# STM32N645 register map
File version: 1.0
CPU: CM55 r0p1, little endian, no MPU, FPU, vendor SysTick, 8 interrupt priority bits
Registers are 32-bit, read-write, reset 0x0 unless marked. A register's access mark holds for its fields unless they carry their own. Offsets are from the block's base; [hi:lo] are bit positions; {n}, {i} and the like mark numbered series; 'fields as' and 'values as' point back to an identical list.

## JPEG — JPEG codec
Base 0x48023000
Same registers: JPEG_S 0x58023000
0x00 CONFR0 wo — JPEG codec control register
  [0] START
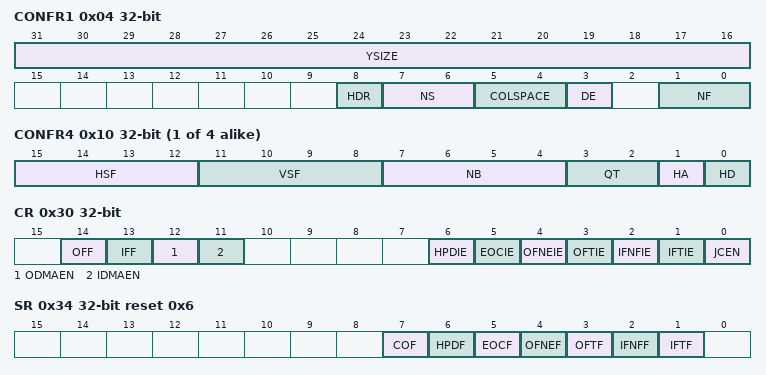
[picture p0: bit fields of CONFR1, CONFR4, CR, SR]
0x04 CONFR1 — JPEG codec configuration register 1
  [31:16] YSIZE
  [8] HDR — Header processing
  [7:6] NS — Number of components for scan
  [5:4] COLSPACE — Color space
  [3] DE — Codec operation as coder or decoder
  [1:0] NF — Number of color components
0x08 CONFR2 — JPEG codec configuration register 2
  [25:0] NMCU — Number of MCUs
0x0C CONFR3 — JPEG codec configuration register 3
  [31:16] XSIZE
{0x0+4i} CONFR{i} (i=4..7) — JPEG codec configuration register {i}
  [15:12] HSF — Horizontal sampling factor
  [11:8] VSF — Vertical sampling factor
  [7:4] NB — Number of blocks
  [3:2] QT — Quantization table
  [1] HA — Huffman AC
  [0] HD — Huffman DC
0x30 CR access per field — JPEG control register
  [14] OFF wo — Output FIFO flush
  [13] IFF wo — Input FIFO flush
  [12] ODMAEN rw — Output DMA enable
  [11] IDMAEN rw — Input DMA enable
  [6] HPDIE rw — Header parsing done interrupt enable
  [5] EOCIE rw — End of conversion interrupt enable
  [4] OFNEIE rw — Output FIFO not empty interrupt enable
  [3] OFTIE rw — Output FIFO threshold interrupt enable
  [2] IFNFIE rw — Input FIFO not full interrupt enable
  [1] IFTIE rw — Input FIFO threshold interrupt enable
  [0] JCEN rw — JPEG core enable
0x34 SR ro reset 0x6 — JPEG status register
  [7] COF — Codec operation flag
  [6] HPDF — Header parsing done flag
  [5] EOCF — End of conversion flag
  [4] OFNEF — Output FIFO not empty flag
  [3] OFTF — Output FIFO threshold flag
  [2] IFNFF — Input FIFO not full flag
  [1] IFTF — Input FIFO threshold flag
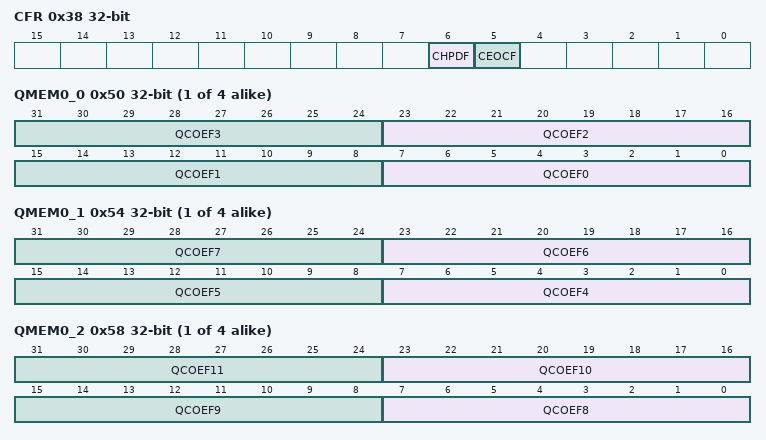
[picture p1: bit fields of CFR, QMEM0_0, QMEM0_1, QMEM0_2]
0x38 CFR — JPEG clear flag register
  [6] CHPDF — Clear header parsing done flag
  [5] CEOCF — Clear end of conversion flag
0x40 DIR wo — JPEG data input register
  [31:0] DATAIN — Data input FIFO
0x44 DOR ro — JPEG data output register
  [31:0] DATAOUT — Data output FIFO
{0x50+0x40*i} QMEM{i}_0 reset not defined (i=0..3) — JPEG quantization memory {i}
  [8n+7:8n] QCOEF{n} (n=0..3) — Quantization coefficient {n}
{0x54+0x40*i} QMEM{i}_1 reset not defined (i=0..3) — JPEG quantization memory {i}
  [8n-25:8n-32] QCOEF{n} (n=4..7) — Quantization coefficient {n}
{0x58+0x40*i} QMEM{i}_2 reset not defined (i=0..3) — JPEG quantization memory {i}
  [8n-57:8n-64] QCOEF{n} (n=8..11) — Quantization coefficient {n}
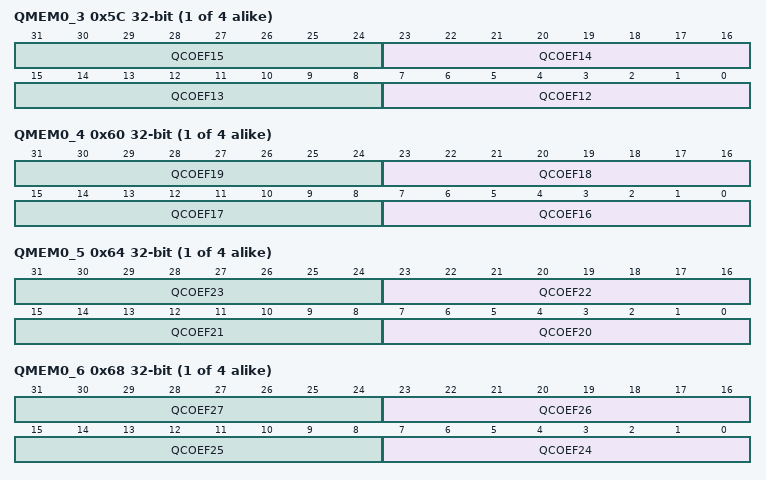
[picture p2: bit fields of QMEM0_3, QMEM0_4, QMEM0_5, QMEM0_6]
{0x5C+0x40*i} QMEM{i}_3 reset not defined (i=0..3) — JPEG quantization memory {i}
  [8n-89:8n-96] QCOEF{n} (n=12..15) — Quantization coefficient {n}
{0x60+0x40*i} QMEM{i}_4 reset not defined (i=0..3) — JPEG quantization memory {i}
  [8n-121:8n-128] QCOEF{n} (n=16..19) — Quantization coefficient {n}
{0x64+0x40*i} QMEM{i}_5 reset not defined (i=0..3) — JPEG quantization memory {i}
  [8n-153:8n-160] QCOEF{n} (n=20..23) — Quantization coefficient {n}
{0x68+0x40*i} QMEM{i}_6 reset not defined (i=0..3) — JPEG quantization memory {i}
  [8n-185:8n-192] QCOEF{n} (n=24..27) — Quantization coefficient {n}
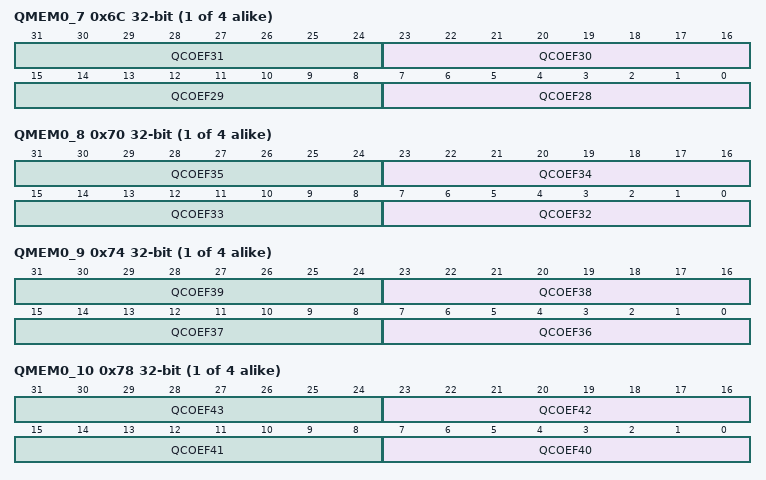
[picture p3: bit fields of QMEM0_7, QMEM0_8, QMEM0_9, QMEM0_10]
{0x6C+0x40*i} QMEM{i}_7 reset not defined (i=0..3) — JPEG quantization memory {i}
  [8n-217:8n-224] QCOEF{n} (n=28..31) — Quantization coefficient {n}
{0x70+0x40*i} QMEM{i}_8 reset not defined (i=0..3) — JPEG quantization memory {i}
  [8n-249:8n-256] QCOEF{n} (n=32..35) — Quantization coefficient {n}
{0x74+0x40*i} QMEM{i}_9 reset not defined (i=0..3) — JPEG quantization memory {i}
  [8n-281:8n-288] QCOEF{n} (n=36..39) — Quantization coefficient {n}
{0x78+0x40*i} QMEM{i}_10 reset not defined (i=0..3) — JPEG quantization memory {i}
  [8n-313:8n-320] QCOEF{n} (n=40..43) — Quantization coefficient {n}
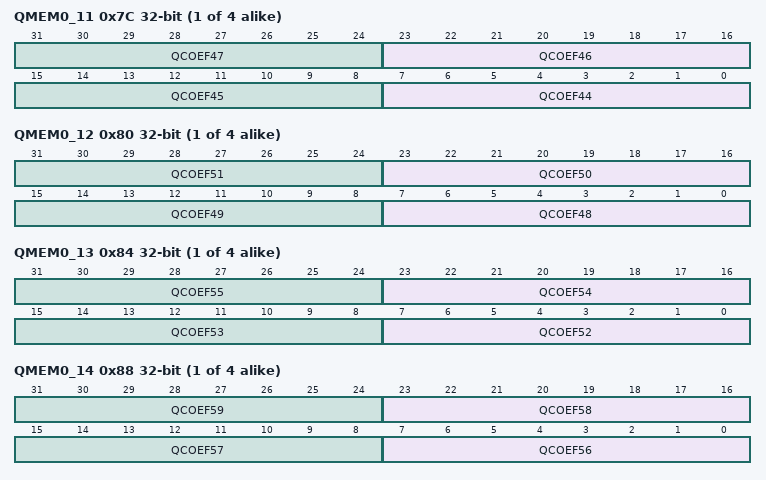
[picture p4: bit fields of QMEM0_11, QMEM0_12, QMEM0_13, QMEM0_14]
{0x7C+0x40*i} QMEM{i}_11 reset not defined (i=0..3) — JPEG quantization memory {i}
  [8n-345:8n-352] QCOEF{n} (n=44..47) — Quantization coefficient {n}
{0x80+0x40*i} QMEM{i}_12 reset not defined (i=0..3) — JPEG quantization memory {i}
  [8n-377:8n-384] QCOEF{n} (n=48..51) — Quantization coefficient {n}
{0x84+0x40*i} QMEM{i}_13 reset not defined (i=0..3) — JPEG quantization memory {i}
  [8n-409:8n-416] QCOEF{n} (n=52..55) — Quantization coefficient {n}
{0x88+0x40*i} QMEM{i}_14 reset not defined (i=0..3) — JPEG quantization memory {i}
  [8n-441:8n-448] QCOEF{n} (n=56..59) — Quantization coefficient {n}
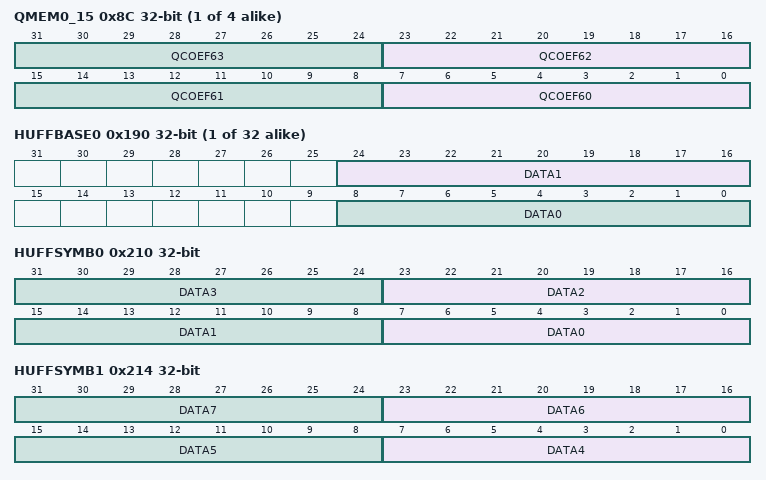
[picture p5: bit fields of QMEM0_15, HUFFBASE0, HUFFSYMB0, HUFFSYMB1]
{0x8C+0x40*i} QMEM{i}_15 reset not defined (i=0..3) — JPEG quantization memory {i}
  [8n-473:8n-480] QCOEF{n} (n=60..63) — Quantization coefficient {n}
{0x150+0x10*i} HUFFMIN{i}_0 reset not defined (i=0..3) — JPEG Huffman min
  [31:0] DATA{i} — Minimum Huffman value
{0x154+0x10*i} HUFFMIN{i}_1 reset not defined (i=0..3) — JPEG Huffman min
  [31:0] DATA{i} — Minimum Huffman value
{0x158+0x10*i} HUFFMIN{i}_2 reset not defined (i=0..3) — JPEG Huffman min
  [31:0] DATA{i} — Minimum Huffman value
{0x15C+0x10*i} HUFFMIN{i}_3 reset not defined (i=0..3) — JPEG Huffman min {i}
  [3:0] DATA{i} — Minimum Huffman value
{0x190+4i} HUFFBASE{i} reset not defined (i=0..31) — JPEG Huffman base
  [24:16] DATA{2i+1}, [8:0] DATA{2i}
0x210 HUFFSYMB0 reset not defined — JPEG Huffman symbol
  [8n+7:8n] DATA{n} (n=0..3)
0x214 HUFFSYMB1 reset not defined — JPEG Huffman symbol
  [8n-25:8n-32] DATA{n} (n=4..7)
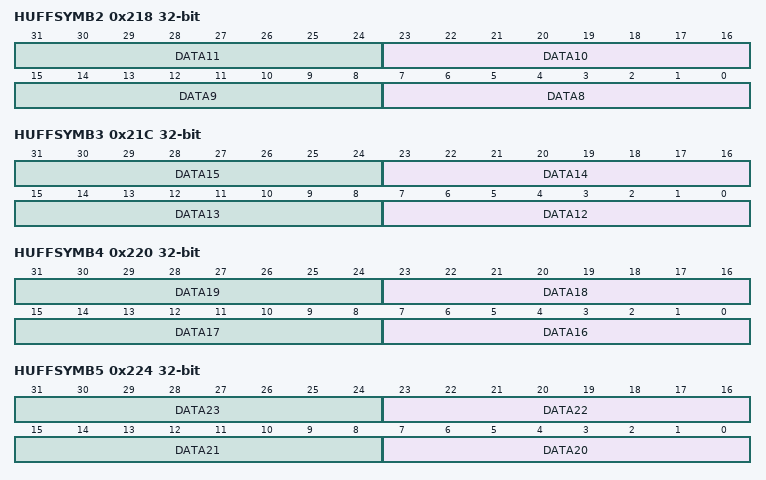
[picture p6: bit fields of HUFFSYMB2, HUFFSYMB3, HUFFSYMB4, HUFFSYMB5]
0x218 HUFFSYMB2 reset not defined — JPEG Huffman symbol
  [8n-57:8n-64] DATA{n} (n=8..11)
0x21C HUFFSYMB3 reset not defined — JPEG Huffman symbol
  [8n-89:8n-96] DATA{n} (n=12..15)
0x220 HUFFSYMB4 reset not defined — JPEG Huffman symbol
  [8n-121:8n-128] DATA{n} (n=16..19)
0x224 HUFFSYMB5 reset not defined — JPEG Huffman symbol
  [8n-153:8n-160] DATA{n} (n=20..23)
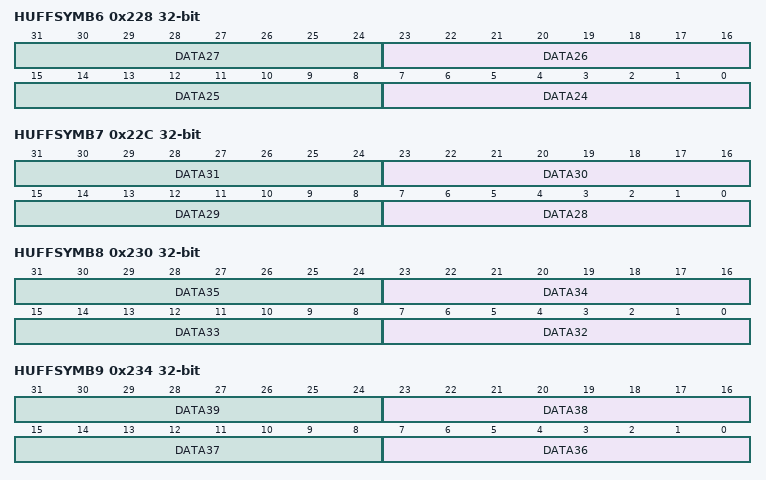
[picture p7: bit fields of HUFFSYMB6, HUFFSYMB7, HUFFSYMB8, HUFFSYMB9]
0x228 HUFFSYMB6 reset not defined — JPEG Huffman symbol
  [8n-185:8n-192] DATA{n} (n=24..27)
0x22C HUFFSYMB7 reset not defined — JPEG Huffman symbol
  [8n-217:8n-224] DATA{n} (n=28..31)
0x230 HUFFSYMB8 reset not defined — JPEG Huffman symbol
  [8n-249:8n-256] DATA{n} (n=32..35)
0x234 HUFFSYMB9 reset not defined — JPEG Huffman symbol
  [8n-281:8n-288] DATA{n} (n=36..39)
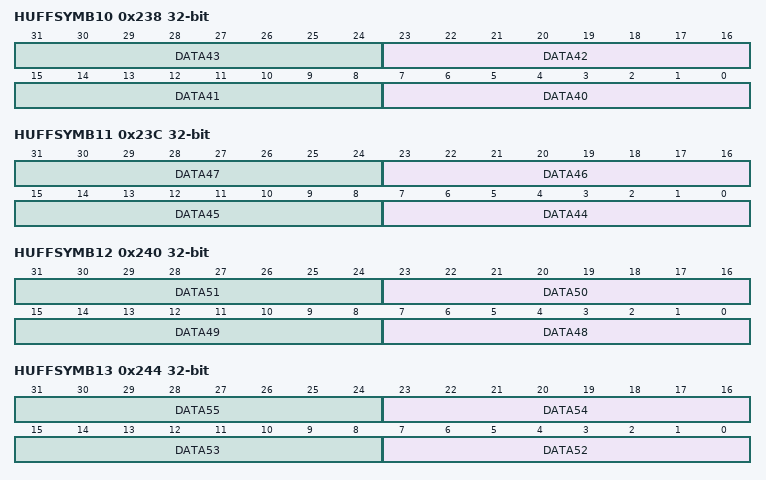
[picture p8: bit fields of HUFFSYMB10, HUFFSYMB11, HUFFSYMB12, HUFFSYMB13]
0x238 HUFFSYMB10 reset not defined — JPEG Huffman symbol
  [8n-313:8n-320] DATA{n} (n=40..43)
0x23C HUFFSYMB11 reset not defined — JPEG Huffman symbol
  [8n-345:8n-352] DATA{n} (n=44..47)
0x240 HUFFSYMB12 reset not defined — JPEG Huffman symbol
  [8n-377:8n-384] DATA{n} (n=48..51)
0x244 HUFFSYMB13 reset not defined — JPEG Huffman symbol
  [8n-409:8n-416] DATA{n} (n=52..55)
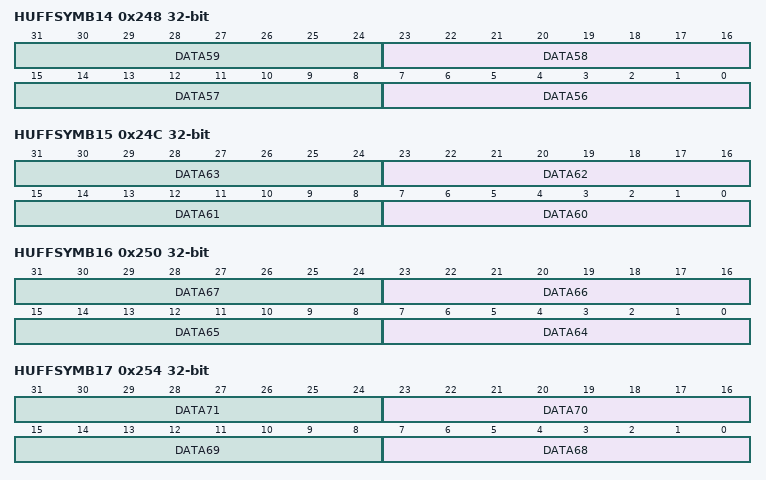
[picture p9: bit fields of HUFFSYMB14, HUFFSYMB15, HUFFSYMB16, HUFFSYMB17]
0x248 HUFFSYMB14 reset not defined — JPEG Huffman symbol
  [8n-441:8n-448] DATA{n} (n=56..59)
0x24C HUFFSYMB15 reset not defined — JPEG Huffman symbol
  [8n-473:8n-480] DATA{n} (n=60..63)
0x250 HUFFSYMB16 reset not defined — JPEG Huffman symbol
  [8n-505:8n-512] DATA{n} (n=64..67)
0x254 HUFFSYMB17 reset not defined — JPEG Huffman symbol
  [8n-537:8n-544] DATA{n} (n=68..71)
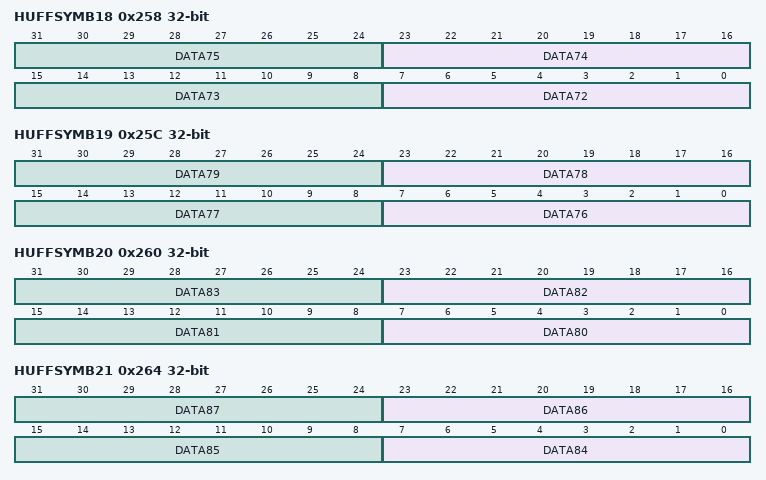
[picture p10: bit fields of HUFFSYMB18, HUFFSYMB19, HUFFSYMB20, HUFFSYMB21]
0x258 HUFFSYMB18 reset not defined — JPEG Huffman symbol
  [8n-569:8n-576] DATA{n} (n=72..75)
0x25C HUFFSYMB19 reset not defined — JPEG Huffman symbol
  [8n-601:8n-608] DATA{n} (n=76..79)
0x260 HUFFSYMB20 reset not defined — JPEG Huffman symbol
  [8n-633:8n-640] DATA{n} (n=80..83)
0x264 HUFFSYMB21 reset not defined — JPEG Huffman symbol
  [8n-665:8n-672] DATA{n} (n=84..87)
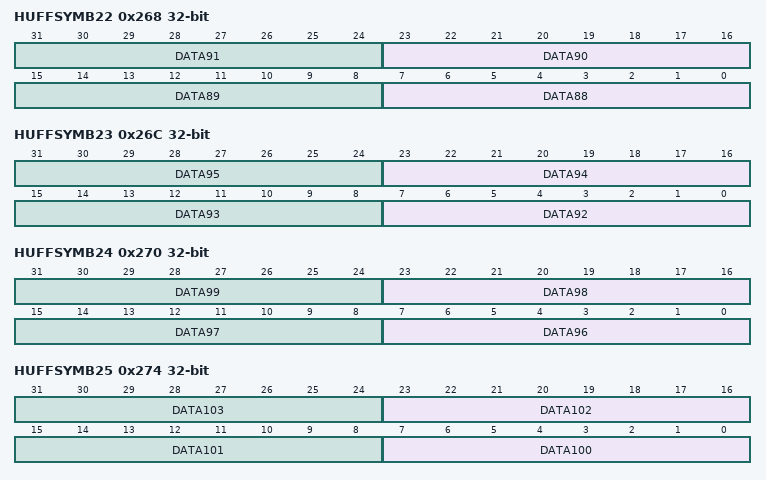
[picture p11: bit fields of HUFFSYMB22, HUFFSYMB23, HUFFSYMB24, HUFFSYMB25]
0x268 HUFFSYMB22 reset not defined — JPEG Huffman symbol
  [8n-697:8n-704] DATA{n} (n=88..91)
0x26C HUFFSYMB23 reset not defined — JPEG Huffman symbol
  [8n-729:8n-736] DATA{n} (n=92..95)
0x270 HUFFSYMB24 reset not defined — JPEG Huffman symbol
  [8n-761:8n-768] DATA{n} (n=96..99)
0x274 HUFFSYMB25 reset not defined — JPEG Huffman symbol
  [8n-793:8n-800] DATA{n} (n=100..103)
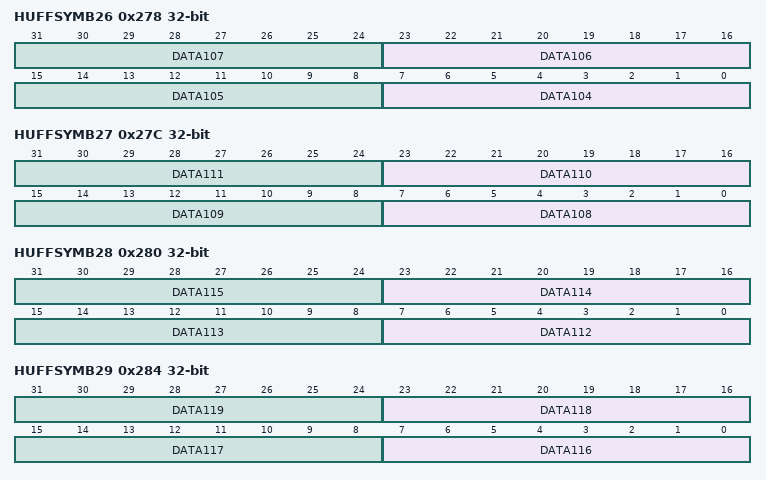
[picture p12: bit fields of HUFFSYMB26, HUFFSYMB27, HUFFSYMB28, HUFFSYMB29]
0x278 HUFFSYMB26 reset not defined — JPEG Huffman symbol
  [8n-825:8n-832] DATA{n} (n=104..107)
0x27C HUFFSYMB27 reset not defined — JPEG Huffman symbol
  [8n-857:8n-864] DATA{n} (n=108..111)
0x280 HUFFSYMB28 reset not defined — JPEG Huffman symbol
  [8n-889:8n-896] DATA{n} (n=112..115)
0x284 HUFFSYMB29 reset not defined — JPEG Huffman symbol
  [8n-921:8n-928] DATA{n} (n=116..119)
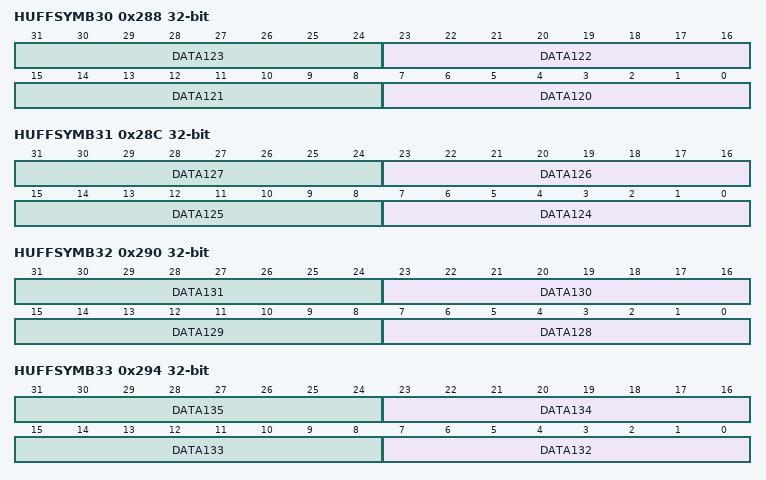
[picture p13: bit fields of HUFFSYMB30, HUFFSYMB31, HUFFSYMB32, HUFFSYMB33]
0x288 HUFFSYMB30 reset not defined — JPEG Huffman symbol
  [8n-953:8n-960] DATA{n} (n=120..123)
0x28C HUFFSYMB31 reset not defined — JPEG Huffman symbol
  [8n-985:8n-992] DATA{n} (n=124..127)
0x290 HUFFSYMB32 reset not defined — JPEG Huffman symbol
  [8n-1017:8n-1024] DATA{n} (n=128..131)
0x294 HUFFSYMB33 reset not defined — JPEG Huffman symbol
  [8n-1049:8n-1056] DATA{n} (n=132..135)
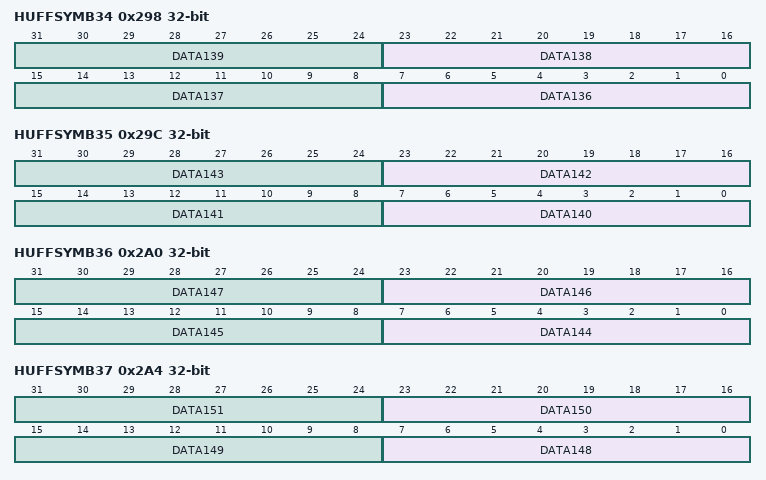
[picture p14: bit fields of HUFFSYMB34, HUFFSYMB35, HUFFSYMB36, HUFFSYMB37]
0x298 HUFFSYMB34 reset not defined — JPEG Huffman symbol
  [8n-1081:8n-1088] DATA{n} (n=136..139)
0x29C HUFFSYMB35 reset not defined — JPEG Huffman symbol
  [8n-1113:8n-1120] DATA{n} (n=140..143)
0x2A0 HUFFSYMB36 reset not defined — JPEG Huffman symbol
  [8n-1145:8n-1152] DATA{n} (n=144..147)
0x2A4 HUFFSYMB37 reset not defined — JPEG Huffman symbol
  [8n-1177:8n-1184] DATA{n} (n=148..151)
0x2A8 HUFFSYMB38 reset not defined — JPEG Huffman symbol
  [8n-1209:8n-1216] DATA{n} (n=152..155)
0x2AC HUFFSYMB39 reset not defined — JPEG Huffman symbol
  [8n-1241:8n-1248] DATA{n} (n=156..159)
0x2B0 HUFFSYMB40 reset not defined — JPEG Huffman symbol
  [8n-1273:8n-1280] DATA{n} (n=160..163)
0x2B4 HUFFSYMB41 reset not defined — JPEG Huffman symbol
  [8n-1305:8n-1312] DATA{n} (n=164..167)
0x2B8 HUFFSYMB42 reset not defined — JPEG Huffman symbol
  [8n-1337:8n-1344] DATA{n} (n=168..171)
0x2BC HUFFSYMB43 reset not defined — JPEG Huffman symbol
  [8n-1369:8n-1376] DATA{n} (n=172..175)
0x2C0 HUFFSYMB44 reset not defined — JPEG Huffman symbol
  [8n-1401:8n-1408] DATA{n} (n=176..179)
0x2C4 HUFFSYMB45 reset not defined — JPEG Huffman symbol
  [8n-1433:8n-1440] DATA{n} (n=180..183)
0x2C8 HUFFSYMB46 reset not defined — JPEG Huffman symbol
  [8n-1465:8n-1472] DATA{n} (n=184..187)
0x2CC HUFFSYMB47 reset not defined — JPEG Huffman symbol
  [8n-1497:8n-1504] DATA{n} (n=188..191)
0x2D0 HUFFSYMB48 reset not defined — JPEG Huffman symbol
  [8n-1529:8n-1536] DATA{n} (n=192..195)
0x2D4 HUFFSYMB49 reset not defined — JPEG Huffman symbol
  [8n-1561:8n-1568] DATA{n} (n=196..199)
0x2D8 HUFFSYMB50 reset not defined — JPEG Huffman symbol
  [8n-1593:8n-1600] DATA{n} (n=200..203)
0x2DC HUFFSYMB51 reset not defined — JPEG Huffman symbol
  [8n-1625:8n-1632] DATA{n} (n=204..207)
0x2E0 HUFFSYMB52 reset not defined — JPEG Huffman symbol
  [8n-1657:8n-1664] DATA{n} (n=208..211)
0x2E4 HUFFSYMB53 reset not defined — JPEG Huffman symbol
  [8n-1689:8n-1696] DATA{n} (n=212..215)
0x2E8 HUFFSYMB54 reset not defined — JPEG Huffman symbol
  [8n-1721:8n-1728] DATA{n} (n=216..219)
0x2EC HUFFSYMB55 reset not defined — JPEG Huffman symbol
  [8n-1753:8n-1760] DATA{n} (n=220..223)
0x2F0 HUFFSYMB56 reset not defined — JPEG Huffman symbol
  [8n-1785:8n-1792] DATA{n} (n=224..227)
0x2F4 HUFFSYMB57 reset not defined — JPEG Huffman symbol
  [8n-1817:8n-1824] DATA{n} (n=228..231)
0x2F8 HUFFSYMB58 reset not defined — JPEG Huffman symbol
  [8n-1849:8n-1856] DATA{n} (n=232..235)
0x2FC HUFFSYMB59 reset not defined — JPEG Huffman symbol
  [8n-1881:8n-1888] DATA{n} (n=236..239)
0x300 HUFFSYMB60 reset not defined — JPEG Huffman symbol
  [8n-1913:8n-1920] DATA{n} (n=240..243)
0x304 HUFFSYMB61 reset not defined — JPEG Huffman symbol
  [8n-1945:8n-1952] DATA{n} (n=244..247)
0x308 HUFFSYMB62 reset not defined — JPEG Huffman symbol
  [8n-1977:8n-1984] DATA{n} (n=248..251)
0x30C HUFFSYMB63 reset not defined — JPEG Huffman symbol
  [8n-2009:8n-2016] DATA{n} (n=252..255)
0x310 HUFFSYMB64 reset not defined — JPEG Huffman symbol
  [8n-2041:8n-2048] DATA{n} (n=256..259)
0x314 HUFFSYMB65 reset not defined — JPEG Huffman symbol
  [8n-2073:8n-2080] DATA{n} (n=260..263)
0x318 HUFFSYMB66 reset not defined — JPEG Huffman symbol
  [8n-2105:8n-2112] DATA{n} (n=264..267)
0x31C HUFFSYMB67 reset not defined — JPEG Huffman symbol
  [8n-2137:8n-2144] DATA{n} (n=268..271)
0x320 HUFFSYMB68 reset not defined — JPEG Huffman symbol
  [8n-2169:8n-2176] DATA{n} (n=272..275)
0x324 HUFFSYMB69 reset not defined — JPEG Huffman symbol
  [8n-2201:8n-2208] DATA{n} (n=276..279)
0x328 HUFFSYMB70 reset not defined — JPEG Huffman symbol
  [8n-2233:8n-2240] DATA{n} (n=280..283)
0x32C HUFFSYMB71 reset not defined — JPEG Huffman symbol
  [8n-2265:8n-2272] DATA{n} (n=284..287)
0x330 HUFFSYMB72 reset not defined — JPEG Huffman symbol
  [8n-2297:8n-2304] DATA{n} (n=288..291)
0x334 HUFFSYMB73 reset not defined — JPEG Huffman symbol
  [8n-2329:8n-2336] DATA{n} (n=292..295)
0x338 HUFFSYMB74 reset not defined — JPEG Huffman symbol
  [8n-2361:8n-2368] DATA{n} (n=296..299)
0x33C HUFFSYMB75 reset not defined — JPEG Huffman symbol
  [8n-2393:8n-2400] DATA{n} (n=300..303)
0x340 HUFFSYMB76 reset not defined — JPEG Huffman symbol
  [8n-2425:8n-2432] DATA{n} (n=304..307)
0x344 HUFFSYMB77 reset not defined — JPEG Huffman symbol
  [8n-2457:8n-2464] DATA{n} (n=308..311)
0x348 HUFFSYMB78 reset not defined — JPEG Huffman symbol
  [8n-2489:8n-2496] DATA{n} (n=312..315)
0x34C HUFFSYMB79 reset not defined — JPEG Huffman symbol
  [8n-2521:8n-2528] DATA{n} (n=316..319)
0x350 HUFFSYMB80 reset not defined — JPEG Huffman symbol
  [8n-2553:8n-2560] DATA{n} (n=320..323)
0x354 HUFFSYMB81 reset not defined — JPEG Huffman symbol
  [8n-2585:8n-2592] DATA{n} (n=324..327)
0x358 HUFFSYMB82 reset not defined — JPEG Huffman symbol
  [8n-2617:8n-2624] DATA{n} (n=328..331)
0x35C HUFFSYMB83 reset not defined — JPEG Huffman symbol
  [8n-2649:8n-2656] DATA{n} (n=332..335)
0x360 DHTMEM0 reset not defined — JPEG DHT memory
  [8n+7:8n] DATA{n} (n=0..3) — Huffman table data {n}
0x364 DHTMEM1 reset not defined — JPEG DHT memory
  [8n-25:8n-32] DATA{n} (n=4..7) — Huffman table data {n}
0x368 DHTMEM2 reset not defined — JPEG DHT memory
  [8n-57:8n-64] DATA{n} (n=8..11) — Huffman table data {n}
0x36C DHTMEM3 reset not defined — JPEG DHT memory
  [8n-89:8n-96] DATA{n} (n=12..15) — Huffman table data {n}
0x370 DHTMEM4 reset not defined — JPEG DHT memory
  [8n-121:8n-128] DATA{n} (n=16..19) — Huffman table data {n}
0x374 DHTMEM5 reset not defined — JPEG DHT memory
  [8n-153:8n-160] DATA{n} (n=20..23) — Huffman table data {n}
0x378 DHTMEM6 reset not defined — JPEG DHT memory
  [8n-185:8n-192] DATA{n} (n=24..27) — Huffman table data {n}
0x37C DHTMEM7 reset not defined — JPEG DHT memory
  [8n-217:8n-224] DATA{n} (n=28..31) — Huffman table data {n}
0x380 DHTMEM8 reset not defined — JPEG DHT memory
  [8n-249:8n-256] DATA{n} (n=32..35) — Huffman table data {n}
0x384 DHTMEM9 reset not defined — JPEG DHT memory
  [8n-281:8n-288] DATA{n} (n=36..39) — Huffman table data {n}
0x388 DHTMEM10 reset not defined — JPEG DHT memory
  [8n-313:8n-320] DATA{n} (n=40..43) — Huffman table data {n}
0x38C DHTMEM11 reset not defined — JPEG DHT memory
  [8n-345:8n-352] DATA{n} (n=44..47) — Huffman table data {n}
0x390 DHTMEM12 reset not defined — JPEG DHT memory
  [8n-377:8n-384] DATA{n} (n=48..51) — Huffman table data {n}
0x394 DHTMEM13 reset not defined — JPEG DHT memory
  [8n-409:8n-416] DATA{n} (n=52..55) — Huffman table data {n}
0x398 DHTMEM14 reset not defined — JPEG DHT memory
  [8n-441:8n-448] DATA{n} (n=56..59) — Huffman table data {n}
0x39C DHTMEM15 reset not defined — JPEG DHT memory
  [8n-473:8n-480] DATA{n} (n=60..63) — Huffman table data {n}
0x3A0 DHTMEM16 reset not defined — JPEG DHT memory
  [8n-505:8n-512] DATA{n} (n=64..67) — Huffman table data {n}
0x3A4 DHTMEM17 reset not defined — JPEG DHT memory
  [8n-537:8n-544] DATA{n} (n=68..71) — Huffman table data {n}
0x3A8 DHTMEM18 reset not defined — JPEG DHT memory
  [8n-569:8n-576] DATA{n} (n=72..75) — Huffman table data {n}
0x3AC DHTMEM19 reset not defined — JPEG DHT memory
  [8n-601:8n-608] DATA{n} (n=76..79) — Huffman table data {n}
0x3B0 DHTMEM20 reset not defined — JPEG DHT memory
  [8n-633:8n-640] DATA{n} (n=80..83) — Huffman table data {n}
0x3B4 DHTMEM21 reset not defined — JPEG DHT memory
  [8n-665:8n-672] DATA{n} (n=84..87) — Huffman table data {n}
0x3B8 DHTMEM22 reset not defined — JPEG DHT memory
  [8n-697:8n-704] DATA{n} (n=88..91) — Huffman table data {n}
0x3BC DHTMEM23 reset not defined — JPEG DHT memory
  [8n-729:8n-736] DATA{n} (n=92..95) — Huffman table data {n}
0x3C0 DHTMEM24 reset not defined — JPEG DHT memory
  [8n-761:8n-768] DATA{n} (n=96..99) — Huffman table data {n}
0x3C4 DHTMEM25 reset not defined — JPEG DHT memory
  [8n-793:8n-800] DATA{n} (n=100..103) — Huffman table data {n}
0x3C8 DHTMEM26 reset not defined — JPEG DHT memory
  [8n-825:8n-832] DATA{n} (n=104..107) — Huffman table data {n}
0x3CC DHTMEM27 reset not defined — JPEG DHT memory
  [8n-857:8n-864] DATA{n} (n=108..111) — Huffman table data {n}
0x3D0 DHTMEM28 reset not defined — JPEG DHT memory
  [8n-889:8n-896] DATA{n} (n=112..115) — Huffman table data {n}
0x3D4 DHTMEM29 reset not defined — JPEG DHT memory
  [8n-921:8n-928] DATA{n} (n=116..119) — Huffman table data {n}
0x3D8 DHTMEM30 reset not defined — JPEG DHT memory
  [8n-953:8n-960] DATA{n} (n=120..123) — Huffman table data {n}
0x3DC DHTMEM31 reset not defined — JPEG DHT memory
  [8n-985:8n-992] DATA{n} (n=124..127) — Huffman table data {n}
0x3E0 DHTMEM32 reset not defined — JPEG DHT memory
  [8n-1017:8n-1024] DATA{n} (n=128..131) — Huffman table data {n}
0x3E4 DHTMEM33 reset not defined — JPEG DHT memory
  [8n-1049:8n-1056] DATA{n} (n=132..135) — Huffman table data {n}
0x3E8 DHTMEM34 reset not defined — JPEG DHT memory
  [8n-1081:8n-1088] DATA{n} (n=136..139) — Huffman table data {n}
0x3EC DHTMEM35 reset not defined — JPEG DHT memory
  [8n-1113:8n-1120] DATA{n} (n=140..143) — Huffman table data {n}
0x3F0 DHTMEM36 reset not defined — JPEG DHT memory
  [8n-1145:8n-1152] DATA{n} (n=144..147) — Huffman table data {n}
0x3F4 DHTMEM37 reset not defined — JPEG DHT memory
  [8n-1177:8n-1184] DATA{n} (n=148..151) — Huffman table data {n}
0x3F8 DHTMEM38 reset not defined — JPEG DHT memory
  [8n-1209:8n-1216] DATA{n} (n=152..155) — Huffman table data {n}
0x3FC DHTMEM39 reset not defined — JPEG DHT memory
  [8n-1241:8n-1248] DATA{n} (n=156..159) — Huffman table data {n}
0x400 DHTMEM40 reset not defined — JPEG DHT memory
  [8n-1273:8n-1280] DATA{n} (n=160..163) — Huffman table data {n}
0x404 DHTMEM41 reset not defined — JPEG DHT memory
  [8n-1305:8n-1312] DATA{n} (n=164..167) — Huffman table data {n}
0x408 DHTMEM42 reset not defined — JPEG DHT memory
  [8n-1337:8n-1344] DATA{n} (n=168..171) — Huffman table data {n}
0x40C DHTMEM43 reset not defined — JPEG DHT memory
  [8n-1369:8n-1376] DATA{n} (n=172..175) — Huffman table data {n}
0x410 DHTMEM44 reset not defined — JPEG DHT memory
  [8n-1401:8n-1408] DATA{n} (n=176..179) — Huffman table data {n}
0x414 DHTMEM45 reset not defined — JPEG DHT memory
  [8n-1433:8n-1440] DATA{n} (n=180..183) — Huffman table data {n}
0x418 DHTMEM46 reset not defined — JPEG DHT memory
  [8n-1465:8n-1472] DATA{n} (n=184..187) — Huffman table data {n}
0x41C DHTMEM47 reset not defined — JPEG DHT memory
  [8n-1497:8n-1504] DATA{n} (n=188..191) — Huffman table data {n}
0x420 DHTMEM48 reset not defined — JPEG DHT memory
  [8n-1529:8n-1536] DATA{n} (n=192..195) — Huffman table data {n}
0x424 DHTMEM49 reset not defined — JPEG DHT memory
  [8n-1561:8n-1568] DATA{n} (n=196..199) — Huffman table data {n}
0x428 DHTMEM50 reset not defined — JPEG DHT memory
  [8n-1593:8n-1600] DATA{n} (n=200..203) — Huffman table data {n}
0x42C DHTMEM51 reset not defined — JPEG DHT memory
  [8n-1625:8n-1632] DATA{n} (n=204..207) — Huffman table data {n}
0x430 DHTMEM52 reset not defined — JPEG DHT memory
  [8n-1657:8n-1664] DATA{n} (n=208..211) — Huffman table data {n}
0x434 DHTMEM53 reset not defined — JPEG DHT memory
  [8n-1689:8n-1696] DATA{n} (n=212..215) — Huffman table data {n}
0x438 DHTMEM54 reset not defined — JPEG DHT memory
  [8n-1721:8n-1728] DATA{n} (n=216..219) — Huffman table data {n}
0x43C DHTMEM55 reset not defined — JPEG DHT memory
  [8n-1753:8n-1760] DATA{n} (n=220..223) — Huffman table data {n}
0x440 DHTMEM56 reset not defined — JPEG DHT memory
  [8n-1785:8n-1792] DATA{n} (n=224..227) — Huffman table data {n}
0x444 DHTMEM57 reset not defined — JPEG DHT memory
  [8n-1817:8n-1824] DATA{n} (n=228..231) — Huffman table data {n}
0x448 DHTMEM58 reset not defined — JPEG DHT memory
  [8n-1849:8n-1856] DATA{n} (n=232..235) — Huffman table data {n}
0x44C DHTMEM59 reset not defined — JPEG DHT memory
  [8n-1881:8n-1888] DATA{n} (n=236..239) — Huffman table data {n}
0x450 DHTMEM60 reset not defined — JPEG DHT memory
  [8n-1913:8n-1920] DATA{n} (n=240..243) — Huffman table data {n}
0x454 DHTMEM61 reset not defined — JPEG DHT memory
  [8n-1945:8n-1952] DATA{n} (n=244..247) — Huffman table data {n}
0x458 DHTMEM62 reset not defined — JPEG DHT memory
  [8n-1977:8n-1984] DATA{n} (n=248..251) — Huffman table data {n}
0x45C DHTMEM63 reset not defined — JPEG DHT memory
  [8n-2009:8n-2016] DATA{n} (n=252..255) — Huffman table data {n}
0x460 DHTMEM64 reset not defined — JPEG DHT memory
  [8n-2041:8n-2048] DATA{n} (n=256..259) — Huffman table data {n}
0x464 DHTMEM65 reset not defined — JPEG DHT memory
  [8n-2073:8n-2080] DATA{n} (n=260..263) — Huffman table data {n}
0x468 DHTMEM66 reset not defined — JPEG DHT memory
  [8n-2105:8n-2112] DATA{n} (n=264..267) — Huffman table data {n}
0x46C DHTMEM67 reset not defined — JPEG DHT memory
  [8n-2137:8n-2144] DATA{n} (n=268..271) — Huffman table data {n}
0x470 DHTMEM68 reset not defined — JPEG DHT memory
  [8n-2169:8n-2176] DATA{n} (n=272..275) — Huffman table data {n}
0x474 DHTMEM69 reset not defined — JPEG DHT memory
  [8n-2201:8n-2208] DATA{n} (n=276..279) — Huffman table data {n}
0x478 DHTMEM70 reset not defined — JPEG DHT memory
  [8n-2233:8n-2240] DATA{n} (n=280..283) — Huffman table data {n}
0x47C DHTMEM71 reset not defined — JPEG DHT memory
  [8n-2265:8n-2272] DATA{n} (n=284..287) — Huffman table data {n}
0x480 DHTMEM72 reset not defined — JPEG DHT memory
  [8n-2297:8n-2304] DATA{n} (n=288..291) — Huffman table data {n}
0x484 DHTMEM73 reset not defined — JPEG DHT memory
  [8n-2329:8n-2336] DATA{n} (n=292..295) — Huffman table data {n}
0x488 DHTMEM74 reset not defined — JPEG DHT memory
  [8n-2361:8n-2368] DATA{n} (n=296..299) — Huffman table data {n}
0x48C DHTMEM75 reset not defined — JPEG DHT memory
  [8n-2393:8n-2400] DATA{n} (n=300..303) — Huffman table data {n}
0x490 DHTMEM76 reset not defined — JPEG DHT memory
  [8n-2425:8n-2432] DATA{n} (n=304..307) — Huffman table data {n}
0x494 DHTMEM77 reset not defined — JPEG DHT memory
  [8n-2457:8n-2464] DATA{n} (n=308..311) — Huffman table data {n}
0x498 DHTMEM78 reset not defined — JPEG DHT memory
  [8n-2489:8n-2496] DATA{n} (n=312..315) — Huffman table data {n}
0x49C DHTMEM79 reset not defined — JPEG DHT memory
  [8n-2521:8n-2528] DATA{n} (n=316..319) — Huffman table data {n}
0x4A0 DHTMEM80 reset not defined — JPEG DHT memory
  [8n-2553:8n-2560] DATA{n} (n=320..323) — Huffman table data {n}
0x4A4 DHTMEM81 reset not defined — JPEG DHT memory
  [8n-2585:8n-2592] DATA{n} (n=324..327) — Huffman table data {n}
0x4A8 DHTMEM82 reset not defined — JPEG DHT memory
  [8n-2617:8n-2624] DATA{n} (n=328..331) — Huffman table data {n}
0x4AC DHTMEM83 reset not defined — JPEG DHT memory
  [8n-2649:8n-2656] DATA{n} (n=332..335) — Huffman table data {n}
0x4B0 DHTMEM84 reset not defined — JPEG DHT memory
  [8n-2681:8n-2688] DATA{n} (n=336..339) — Huffman table data {n}
0x4B4 DHTMEM85 reset not defined — JPEG DHT memory
  [8n-2713:8n-2720] DATA{n} (n=340..343) — Huffman table data {n}
0x4B8 DHTMEM86 reset not defined — JPEG DHT memory
  [8n-2745:8n-2752] DATA{n} (n=344..347) — Huffman table data {n}
0x4BC DHTMEM87 reset not defined — JPEG DHT memory
  [8n-2777:8n-2784] DATA{n} (n=348..351) — Huffman table data {n}
0x4C0 DHTMEM88 reset not defined — JPEG DHT memory
  [8n-2809:8n-2816] DATA{n} (n=352..355) — Huffman table data {n}
0x4C4 DHTMEM89 reset not defined — JPEG DHT memory
  [8n-2841:8n-2848] DATA{n} (n=356..359) — Huffman table data {n}
0x4C8 DHTMEM90 reset not defined — JPEG DHT memory
  [8n-2873:8n-2880] DATA{n} (n=360..363) — Huffman table data {n}
0x4CC DHTMEM91 reset not defined — JPEG DHT memory
  [8n-2905:8n-2912] DATA{n} (n=364..367) — Huffman table data {n}
0x4D0 DHTMEM92 reset not defined — JPEG DHT memory
  [8n-2937:8n-2944] DATA{n} (n=368..371) — Huffman table data {n}
0x4D4 DHTMEM93 reset not defined — JPEG DHT memory
  [8n-2969:8n-2976] DATA{n} (n=372..375) — Huffman table data {n}
0x4D8 DHTMEM94 reset not defined — JPEG DHT memory
  [8n-3001:8n-3008] DATA{n} (n=376..379) — Huffman table data {n}
0x4DC DHTMEM95 reset not defined — JPEG DHT memory
  [8n-3033:8n-3040] DATA{n} (n=380..383) — Huffman table data {n}
0x4E0 DHTMEM96 reset not defined — JPEG DHT memory
  [8n-3065:8n-3072] DATA{n} (n=384..387) — Huffman table data {n}
0x4E4 DHTMEM97 reset not defined — JPEG DHT memory
  [8n-3097:8n-3104] DATA{n} (n=388..391) — Huffman table data {n}
0x4E8 DHTMEM98 reset not defined — JPEG DHT memory
  [8n-3129:8n-3136] DATA{n} (n=392..395) — Huffman table data {n}
0x4EC DHTMEM99 reset not defined — JPEG DHT memory
  [8n-3161:8n-3168] DATA{n} (n=396..399) — Huffman table data {n}
0x4F0 DHTMEM100 reset not defined — JPEG DHT memory
  [8n-3193:8n-3200] DATA{n} (n=400..403) — Huffman table data {n}
0x4F4 DHTMEM101 reset not defined — JPEG DHT memory
  [8n-3225:8n-3232] DATA{n} (n=404..407) — Huffman table data {n}
0x4F8 DHTMEM102 reset not defined — JPEG DHT memory
  [8n-3257:8n-3264] DATA{n} (n=408..411) — Huffman table data {n}
{0x500+4i} HUFFENC_AC0_{i} reset not defined (i=0..87) — JPEG Huffman encoder AC0
  [27:24] HLEN{2i+1} — Huffman length {2i+1}
  [23:16] HCODE{2i+1} — Huffman code {2i+1}
  [11:8] HLEN{2i} — Huffman length {2i}
  [7:0] HCODE{2i} — Huffman code {2i}
{0x660+4i} HUFFENC_AC1_{i} reset not defined (i=0..87) — JPEG Huffman encoder AC1
  fields as HUFFENC_AC0_0
{0x7C0+4i} HUFFENC_DC0_{i} reset not defined (i=0..7) — JPEG Huffman encoder DC0
  fields as HUFFENC_AC0_0
{0x7E0+4i} HUFFENC_DC1_{i} reset not defined (i=0..7) — JPEG Huffman encoder DC1
  fields as HUFFENC_AC0_0
